AUTOSAR XML (schema 4.0)
package /ADAS_Components
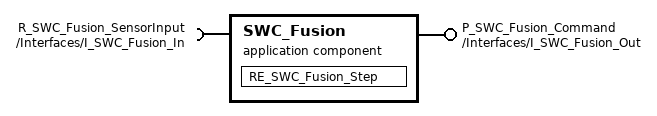
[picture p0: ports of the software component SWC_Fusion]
  application sw component type SWC_Fusion  # AUTOSAR Application SWC SWC_Fusion for ADAS control
    provide port P_SWC_Fusion_Command: provided-interface=/Interfaces/I_SWC_Fusion_Out
    require port R_SWC_Fusion_SensorInput: required-interface=/Interfaces/I_SWC_Fusion_In
    behavior SWC_Fusion_Behavior
      runnable RE_SWC_Fusion_Step: symbol=SWC_Fusion_Step
